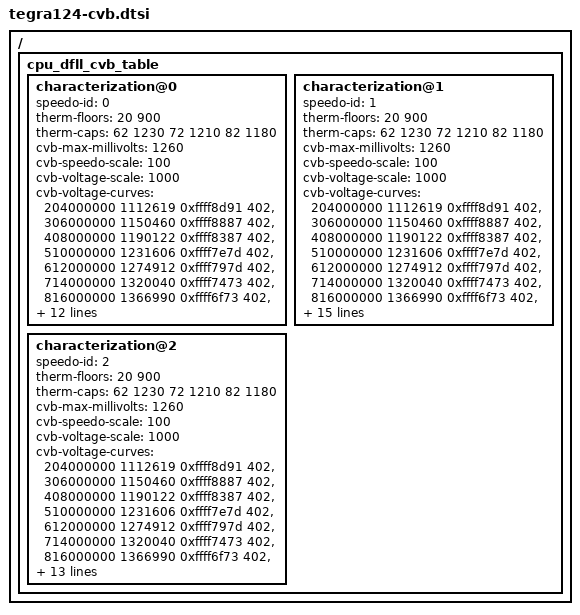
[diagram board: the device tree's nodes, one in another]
/ {
	cpu_dfll_cvb_table {
		#address-cells = <1>;
		#size-cells = <0>;

		characterization@0 {
			speedo-id = <0>;

			therm-floors = < 20 900>;
			therm-caps = < 62 1230 72 1210 82 1180>;
			cvb-max-millivolts = <1260>;
			cvb-speedo-scale = <100>;
			cvb-voltage-scale = <1000>;
			cvb-voltage-curves = < 204000000 1112619 0xffff8d91 402>,
						< 306000000 1150460 0xffff8887 402>,
						< 408000000 1190122 0xffff8387 402>,
						< 510000000 1231606 0xffff7e7d 402>,
						< 612000000 1274912 0xffff797d 402>,
						< 714000000 1320040 0xffff7473 402>,
						< 816000000 1366990 0xffff6f73 402>,
						< 918000000 1415762 0xffff6a69 402>,
						<1020000000 1466355 0xffff6569 402>,
						<1122000000 1518771 0xffff605f 402>,
						<1224000000 1573009 0xffff5b5f 402>,
						<1326000000 1629068 0xffff5655 402>,
						<1428000000 1686950 0xffff5155 402>,
						<1530000000 1746653 0xffff4c4b 402>,
						<1632000000 1808179 0xffff474b 402>,
						<1734000000 1871526 0xffff4241 402>,
						<1836000000 1936696 0xffff3d41 402>,
						<1938000000 2003687 0xffff3837 402>,
						<2014500000 2054787 0xffff3481 402>;
		};

		characterization@1 {
			speedo-id = <1>;

			therm-floors = < 20 900>;
			therm-caps = < 62 1230 72 1210 82 1180>;
			cvb-max-millivolts = <1260>;
			cvb-speedo-scale = <100>;
			cvb-voltage-scale = <1000>;
			cvb-voltage-curves = < 204000000 1112619 0xffff8d91 402>,
						< 306000000 1150460 0xffff8887 402>,
						< 408000000 1190122 0xffff8387 402>,
						< 510000000 1231606 0xffff7e7d 402>,
						< 612000000 1274912 0xffff797d 402>,
						< 714000000 1320040 0xffff7473 402>,
						< 816000000 1366990 0xffff6f73 402>,
						< 918000000 1415762 0xffff6a69 402>,
						<1020000000 1466355 0xffff6569 402>,
						<1122000000 1518771 0xffff605f 402>,
						<1224000000 1573009 0xffff5b5f 402>,
						<1326000000 1629068 0xffff5655 402>,
						<1428000000 1686950 0xffff5155 402>,
						<1530000000 1746653 0xffff4c4b 402>,
						<1632000000 1808179 0xffff474b 402>,
						<1734000000 1871526 0xffff4241 402>,
						<1836000000 1936696 0xffff3d41 402>,
						<1938000000 2003687 0xffff3837 402>,
						<2014500000 2054787 0xffff3481 402>,
						<2116500000 2124957 0xffff2f77 402>,
						<2218500000 2196950 0xffff2a77 402>,
						<2320500000 2270765 0xffff256d 402>;
		};

		characterization@2 {
			speedo-id = <2>;

			therm-floors = < 20 900>;
			therm-caps = < 62 1230 72 1210 82 1180>;
			cvb-max-millivolts = <1260>;
			cvb-speedo-scale = <100>;
			cvb-voltage-scale = <1000>;
			cvb-voltage-curves = < 204000000 1112619 0xffff8d91 402>,
						< 306000000 1150460 0xffff8887 402>,
						< 408000000 1190122 0xffff8387 402>,
						< 510000000 1231606 0xffff7e7d 402>,
						< 612000000 1274912 0xffff797d 402>,
						< 714000000 1320040 0xffff7473 402>,
						< 816000000 1366990 0xffff6f73 402>,
						< 918000000 1415762 0xffff6a69 402>,
						<1020000000 1466355 0xffff6569 402>,
						<1122000000 1518771 0xffff605f 402>,
						<1224000000 1573009 0xffff5b5f 402>,
						<1326000000 1629068 0xffff5655 402>,
						<1428000000 1686950 0xffff5155 402>,
						<1530000000 1746653 0xffff4c4b 402>,
						<1632000000 1808179 0xffff474b 402>,
						<1734000000 1871526 0xffff4241 402>,
						<1836000000 1936696 0xffff3d41 402>,
						<1938000000 2003687 0xffff3837 402>,
						<2014500000 2054787 0xffff3481 402>,
						<2116500000 2124957 0xffff2f77 402>;
		};
	};
};
